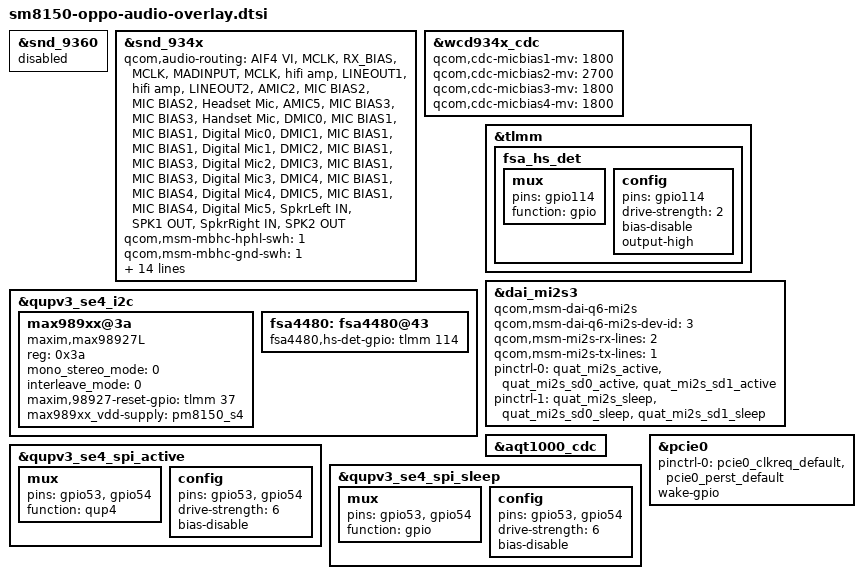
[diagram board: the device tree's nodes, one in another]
/*this is for oppo project different hw version */
&snd_9360 {
	status = "disabled";
};

&snd_934x {
	qcom,audio-routing =
		"AIF4 VI", "MCLK",
		"RX_BIAS", "MCLK",
		"MADINPUT", "MCLK",
		"hifi amp", "LINEOUT1",
		"hifi amp", "LINEOUT2",
		"AMIC2", "MIC BIAS2",
		"MIC BIAS2", "Headset Mic",
		"AMIC5", "MIC BIAS3",
		"MIC BIAS3", "Handset Mic",
		"DMIC0", "MIC BIAS1",
		"MIC BIAS1", "Digital Mic0",
		"DMIC1", "MIC BIAS1",
		"MIC BIAS1", "Digital Mic1",
		"DMIC2", "MIC BIAS1",
		"MIC BIAS3", "Digital Mic2",
		"DMIC3", "MIC BIAS1",
		"MIC BIAS3", "Digital Mic3",
		"DMIC4", "MIC BIAS1",
		"MIC BIAS4", "Digital Mic4",
		"DMIC5", "MIC BIAS1",
		"MIC BIAS4", "Digital Mic5",
		"SpkrLeft IN", "SPK1 OUT",
		"SpkrRight IN", "SPK2 OUT";

	qcom,msm-mbhc-hphl-swh = <1>;
	qcom,msm-mbhc-gnd-swh = <1>;
	qcom,msm-mbhc-hs-mic-max-threshold-mv = <2600>;
	qcom,msm-mbhc-hs-mic-min-threshold-mv = <75>;
	qcom,hph-en0-gpio = <&tavil_hph_en0>;
	qcom,hph-en1-gpio = <&tavil_hph_en1>;
	qcom,tavil-mclk-clk-freq = <9600000>;

	asoc-codec = <&stub_codec>, <&ext_disp_audio_codec>;
	asoc-codec-names = "msm-stub-codec.1",
			   "msm-ext-disp-audio-codec-rx";

	qcom,wsa-disable;
	qcom,wsa-max-devs = <0>;
	oppo,speaker-pa = "maxim";
	qcom,msm-mbhc-usbc-audio-supported = <1>;
	oppo,usbc-switch = <1>;  /* 0: no usbc switch; 1: fsa4480; 2: max20328 */
	fsa4480-i2c-handle = <&fsa4480>;
};

&wcd934x_cdc {
	qcom,cdc-micbias1-mv = <1800>;
	qcom,cdc-micbias2-mv = <2700>;
	qcom,cdc-micbias3-mv = <1800>;
	qcom,cdc-micbias4-mv = <1800>;
};

&qupv3_se4_i2c {
	status = "ok";
	max989xx@3a {
		compatible = "maxim,max98927L";
		reg = <0x3a>;
		mono_stereo_mode = <0>;
		interleave_mode = <0>;
		maxim,98927-reset-gpio = <&tlmm 37 0x00>;
		max989xx_vdd-supply = <&pm8150_s4>;
		status = "okay";
	};

	fsa4480: fsa4480@43 {
		fsa4480,hs-det-gpio = <&tlmm 114 0x00>;
	};
};

&tlmm {
	fsa_hs_det: fsa_hs_det  {
		mux {
			pins = "gpio114";
			function = "gpio";
		};

		config {
			pins = "gpio114";
			drive-strength = <2>;
			bias-disable;
			output-high;
		};
	};
};

&dai_mi2s3 {
	compatible = "qcom,msm-dai-q6-mi2s";
	qcom,msm-dai-q6-mi2s-dev-id = <3>;
	qcom,msm-mi2s-rx-lines = <2>;
	qcom,msm-mi2s-tx-lines = <1>;
	pinctrl-names = "default", "sleep";
	pinctrl-0 = <&quat_mi2s_active &quat_mi2s_sd0_active &quat_mi2s_sd1_active>;
	pinctrl-1 = <&quat_mi2s_sleep &quat_mi2s_sd0_sleep &quat_mi2s_sd1_sleep>;
};

&aqt1000_cdc {
	status = "ok";
};

&qupv3_se4_spi_active {
	mux {
		pins = "gpio53","gpio54";
		function = "qup4";
	};

	config {
		pins =  "gpio53","gpio54";
		drive-strength = <6>;
		bias-disable;
	};
};

&qupv3_se4_spi_sleep {
	mux {
		pins =  "gpio53","gpio54";
		function = "gpio";
	};

	config {
		pins = "gpio53","gpio54";
		drive-strength = <6>;
		bias-disable;
	};
};

&pcie0 {
		pinctrl-0 = <&pcie0_clkreq_default
			&pcie0_perst_default>;
		wake-gpio;
};
